# ATSAMR21E16A register map
Vendor: Atmel Corporation; Series: SAMR21; File version: A
CPU: CM0+ r0p1, little endian, no MPU, no FPU, VTOR, 2 interrupt priority bits
Registers are 8-bit, read-write, reset 0x0 unless marked. A register's access mark holds for its fields unless they carry their own. Offsets are from the block's base; [hi:lo] are bit positions; {n}, {i} and the like mark numbered series; 'fields as' and 'values as' point back to an identical list.

## EVSYS — Event System Interface
Base 0x42000400; register names take the prefix EVSYS_
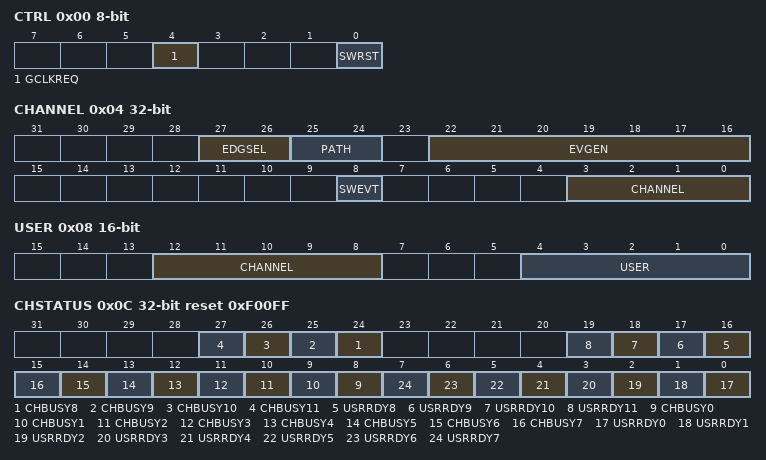
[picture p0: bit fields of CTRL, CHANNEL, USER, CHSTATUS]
0x00 CTRL wo — Control
  [4] GCLKREQ — Generic Clock Requests
  [0] SWRST — Software Reset
0x04 CHANNEL 32-bit
  [27:26] EDGSEL — Edge Detection Selection
    0=NO_EVT_OUTPUT (No event output when using the resynchronized or synchronous path); 1=RISING_EDGE (Event detection only on the rising edge of the signal from the event generator when using the resynchronized or synchronous path); 2=FALLING_EDGE (Event detection only on the falling edge of the signal from the event generator when using the resynchronized or synchronous path); 3=BOTH_EDGES (Event detection on rising and falling edges of the signal from the event generator when using the resynchronized or synchronous path)
  [25:24] PATH — Path Selection
    0=SYNCHRONOUS (Synchronous path); 1=RESYNCHRONIZED (Resynchronized path); 2=ASYNCHRONOUS (Asynchronous path)
  [22:16] EVGEN — Event Generator Selection
  [8] SWEVT — Software Event
  [3:0] CHANNEL — Channel Selection
0x08 USER 16-bit — User Multiplexer
  [12:8] CHANNEL — Channel Event Selection
    0=No Channel Output Selected
  [4:0] USER — User Multiplexer Selection
0x0C CHSTATUS 32-bit ro reset 0xF00FF — Channel Status
  [n+16] CHBUSY{n} (n=8..11) — Channel {n} Busy
  [n+8] USRRDY{n} (n=8..11) — Channel {n} User Ready
  [n+8] CHBUSY{n} (n=0..7) — Channel {n} Busy
  [n] USRRDY{n} (n=0..7) — Channel {n} User Ready
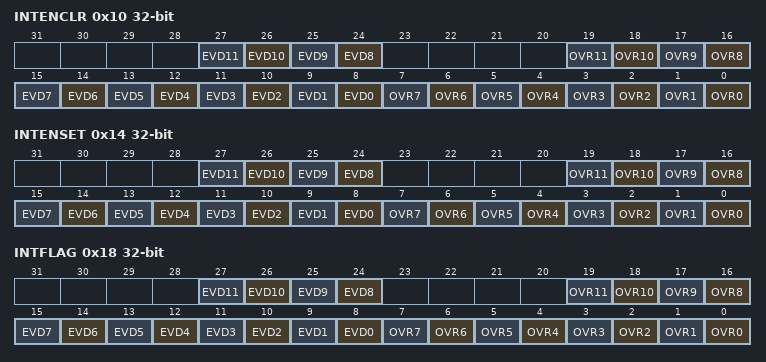
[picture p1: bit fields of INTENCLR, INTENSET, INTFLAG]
0x10 INTENCLR 32-bit — Interrupt Enable Clear
  [n+16] EVD{n} (n=8..11) — Channel {n} Event Detection Interrupt Enable
  [n+8] OVR{n} (n=8..11) — Channel {n} Overrun Interrupt Enable
  [n+8] EVD{n} (n=0..7) — Channel {n} Event Detection Interrupt Enable
  [n] OVR{n} (n=0..7) — Channel {n} Overrun Interrupt Enable
0x14 INTENSET 32-bit — Interrupt Enable Set
  fields as INTENCLR
0x18 INTFLAG 32-bit — Interrupt Flag Status and Clear
  [n+16] EVD{n} (n=8..11) — Channel {n} Event Detection
  [n+8] OVR{n} (n=8..11) — Channel {n} Overrun
  [n+8] EVD{n} (n=0..7) — Channel {n} Event Detection
  [n] OVR{n} (n=0..7) — Channel {n} Overrun

## GCLK — Generic Clock Generator
Base 0x40000C00; register names take the prefix GCLK_
0x00 CTRL — Control
  [0] SWRST — Software Reset
0x01 STATUS ro
  [7] SYNCBUSY — Synchronization Busy Status
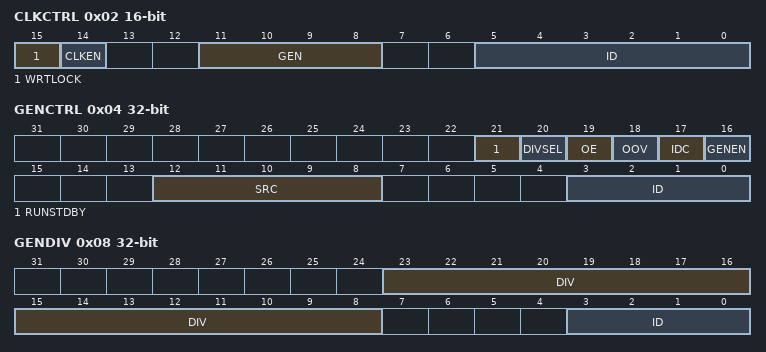
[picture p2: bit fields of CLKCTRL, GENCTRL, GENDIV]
0x02 CLKCTRL 16-bit — Generic Clock Control
  [15] WRTLOCK — Write Lock
  [14] CLKEN — Clock Enable
  [11:8] GEN — Generic Clock Generator
    {v}=GCLK{v} (Generic clock generator {v}) (v=0..7)
  [5:0] ID — Generic Clock Selection ID
0x04 GENCTRL 32-bit — Generic Clock Generator Control
  [21] RUNSTDBY — Run in Standby
  [20] DIVSEL — Divide Selection
  [19] OE — Output Enable
  [18] OOV — Output Off Value
  [17] IDC — Improve Duty Cycle
  [16] GENEN — Generic Clock Generator Enable
  [12:8] SRC — Source Select
    0=XOSC (XOSC oscillator output); 1=GCLKIN (Generator input pad); 2=GCLKGEN1 (Generic clock generator 1 output); 3=OSCULP32K (OSCULP32K oscillator output); 4=OSC32K (OSC32K oscillator output); 5=XOSC32K (XOSC32K oscillator output); 6=OSC8M (OSC8M oscillator output); 7=DFLL48M (DFLL48M output)
  [3:0] ID — Generic Clock Generator Selection
0x08 GENDIV 32-bit — Generic Clock Generator Division
  [23:8] DIV — Division Factor
  [3:0] ID — Generic Clock Generator Selection

## MTB — Cortex-M0+ Micro-Trace Buffer
Base 0x41006000; register names take the prefix MTB_
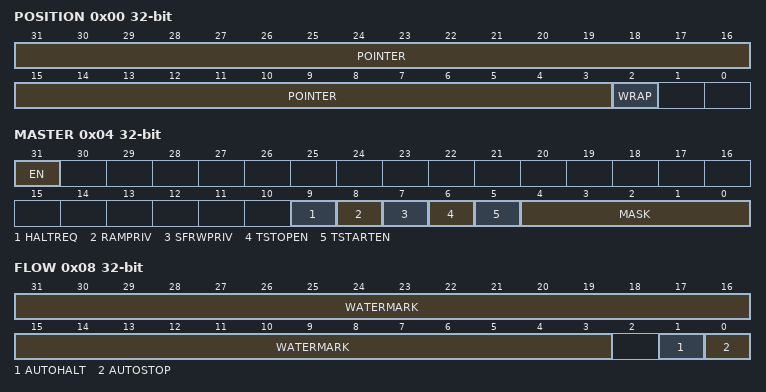
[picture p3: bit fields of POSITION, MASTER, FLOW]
0x00 POSITION 32-bit — MTB Position
  [31:3] POINTER — Trace Packet Location Pointer
  [2] WRAP — Pointer Value Wraps
0x04 MASTER 32-bit — MTB Master
  [31] EN — Main Trace Enable
  [9] HALTREQ — Halt Request
  [8] RAMPRIV — SRAM Privilege
  [7] SFRWPRIV — Special Function Register Write Privilege
  [6] TSTOPEN — Trace Stop Input Enable
  [5] TSTARTEN — Trace Start Input Enable
  [4:0] MASK — Maximum Value of the Trace Buffer in SRAM
0x08 FLOW 32-bit — MTB Flow
  [31:3] WATERMARK — Watermark value
  [1] AUTOHALT — Auto Halt Request
  [0] AUTOSTOP — Auto Stop Tracing
0x0C BASE 32-bit ro — MTB Base
0xF00 ITCTRL 32-bit — MTB Integration Mode Control
0xFA0 CLAIMSET 32-bit — MTB Claim Set
0xFA4 CLAIMCLR 32-bit — MTB Claim Clear
0xFB0 LOCKACCESS 32-bit — MTB Lock Access
0xFB4 LOCKSTATUS 32-bit ro — MTB Lock Status
0xFB8 AUTHSTATUS 32-bit ro — MTB Authentication Status
0xFBC DEVARCH 32-bit ro — MTB Device Architecture
0xFC8 DEVID 32-bit ro — MTB Device Configuration
0xFCC DEVTYPE 32-bit ro — MTB Device Type
{0xFC0+4i} PID{i} 32-bit ro (i=4..7) — CoreSight
{0xFE0+4i} PID{i} 32-bit ro (i=0..3) — CoreSight
{0xFF0+4i} CID{i} 32-bit ro (i=0..3) — CoreSight
